# FX1 register map
Vendor: FTEL; File version: VP_FX1_V3.0_ISP_1.07
Registers are 32-bit, read-write, reset 0x0 unless marked. A register's access mark holds for its fields unless they carry their own. Offsets are from the block's base; [hi:lo] are bit positions; lines under a group give offsets from that group; {n}, {i} and the like mark numbered series.

## ISP (part 1 of 4) — ISP FX1 CSR v1.07 + VP extension 0x20261109 (ISP-UPD-001/002/007); FX1 header is authoritative.
Base 0x11000000
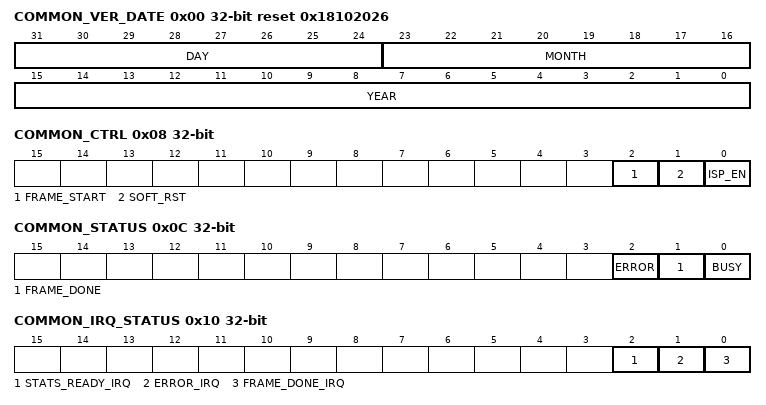
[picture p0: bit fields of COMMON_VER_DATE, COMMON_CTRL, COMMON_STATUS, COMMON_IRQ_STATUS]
0x00 COMMON_VER_DATE ro reset 0x18102026 — Fixed register-map revision date, BCD; not a build timestamp. [access=ro]
  [31:24] DAY — Version Date - Day Day of month, BCD. [access=ro]
  [23:16] MONTH — Version Date - Month Month, BCD. [access=ro]
  [15:0] YEAR — Version Date - Year Year, BCD. Reads 0x2026 for the current map. [access=ro]
0x04 COMMON_VER_ID ro reset 0x10007 — Pipeline programming ABI revision 1.07. Bayer RAW12 statistics, preset-only scaling, channel crop and wide CSC range arithmetic. [access=ro]
  [31:0] VERSION — Pipeline ABI 0x00010007; no per-block revision registers. [access=ro]
0x08 COMMON_CTRL — COMMON: global pipeline control. ISP_EN enables pipeline operation; supported optional blocks also use their own enable controls. [access=mixed]
  [2] FRAME_START write-1-sets — Software Frame Trigger (compatibility) Retained for register compatibility only. A write of 1 is accepted, self-clears and has no effect on the input DMA, admission or any other state. The input DMA starts a frame whenever its head buffer is valid; mark exactly one input buffer valid for single-shot operation. [access=w1s]
  [1] SOFT_RST write-1-sets — Request group recovery: stop admission, drain bus/internal work, then 15-clock reset pulse. Poll COMMON_RECOVERY_STATUS.BUSY/DONE for completion; copy abort records before restart. Busy requests rejected with TUNE_ERROR.PENDING. [access=w1sc]
  [0] ISP_EN — ISP Pipeline Enable 1 enables pipeline operation. Configure geometry and tuning first, then enable the pipeline before arming/enabling DMA so derived output geometry is valid. [access=rw]
0x0C COMMON_STATUS ro — COMMON: global pipeline status, read-only. [access=ro]
  [2] ERROR — Error Present Live OR of DMA_ERR ALIGN/AXI_RD/AXI_WR, LSC_ERROR, EE_STATUS.ERROR and TUNE_ERROR; flow-control and statistics-drop conditions are excluded. See those registers for the cause. [access=ro]
  [1] FRAME_DONE — Frame Complete 1 = the most recently admitted frame has retired on every enabled output, successfully or by recovery. Clears at the next accepted ingress SOF and on reset. [access=ro]
  [0] BUSY — Pipeline Busy 1 = a frame is in flight somewhere in the pipeline. [access=ro]
0x10 COMMON_IRQ_STATUS write-1-clears — COMMON: interrupt status. Sticky; write 1 to clear a bit. A bit sets regardless of the corresponding COMMON_IRQ_EN mask -- the mask gates the interrupt output, not the status. [access=w1c]
  [2] STATS_READY_IRQ write-1-clears — Statistics-Ready Interrupt Status Set when a statistics block publishes a completed frame. Write 1 to clear. [access=w1c]
  [1] ERROR_IRQ write-1-clears — Error Interrupt Status Set when DMA_ERR ALIGN, AXI_RD or AXI_WR, any LSC_ERROR bit, EE_STATUS.ERROR or any TUNE_ERROR bit changes from 0 to 1, and on every accepted recovery of any cause. IDMA_UNDERRUN, ODMA_OVERFLOW and statistics drops do not set it. Write 1 to clear. [access=w1c]
  [0] FRAME_DONE_IRQ write-1-clears — Frame-Done Interrupt Status Set when COMMON_STATUS.FRAME_DONE rises. Write 1 to clear. [access=w1c]
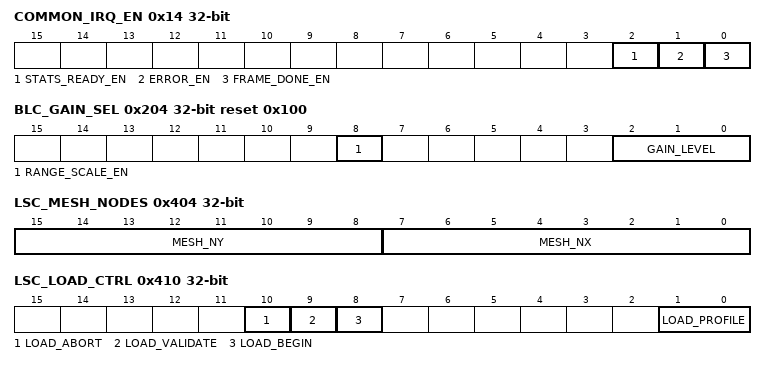
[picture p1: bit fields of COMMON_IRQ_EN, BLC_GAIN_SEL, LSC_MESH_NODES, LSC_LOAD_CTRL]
0x14 COMMON_IRQ_EN — COMMON: interrupt enable mask. Each bit gates whether the matching COMMON_IRQ_STATUS bit drives the interrupt output; the status bit sets either way. [access=rw]
  [2] STATS_READY_EN — Statistics-Ready Interrupt Enable 1 = statistics-ready contributes to the interrupt output. [access=rw]
  [1] ERROR_EN — Error Interrupt Enable 1 = error contributes to the interrupt output. [access=rw]
  [0] FRAME_DONE_EN — Frame-Done Interrupt Enable 1 = frame-done contributes to the interrupt output. [access=rw]
0x18 COMMON_FRAME_WIDTH reset 0x780 — COMMON: input frame width before Bayer phase alignment. The Input Formatter may discard one leading column, then rounds the remaining width down to even. Program legal DMA geometry. Input-domain changes require stopped/drained legacy mode; reject in profile mode with MODE, preserve state. Accepted changes invalidate dependent LSC/EE residents and output geometry. [access=rw]
  [15:0] H_ACTIVE — External Samples Per Line Even external input width before Bayer phase trim, 32..3842. Active W=(Win-SH)&~1 must be 32..3840. IDMA reads the external width; downstream coordinates use the derived active width. [access=rw]
0x1C COMMON_FRAME_HEIGHT reset 0x438 — COMMON: input frame height before Bayer phase alignment. The Input Formatter may discard one leading row, then rounds the remaining height down to even. Input DMA requires an even input height. Input-domain changes require stopped/drained legacy mode; reject in profile mode with MODE, preserve state. Accepted changes invalidate dependent LSC/EE residents and output geometry. [access=rw]
  [15:0] V_ACTIVE — External Lines Per Frame Even external input height before Bayer phase trim, 32..2162. Active H=(Hin-SV)&~1 must be 32..2160. IDMA reads the external height; downstream coordinates use the derived active height. [access=rw]
0x20 COMMON_BAYER — COMMON: Bayer phase of the incoming raw image. The Input Formatter aligns to RGGB by optional leading-column/row removal, then rounds each remaining dimension down to even. Input-domain changes require stopped/drained legacy mode; reject in profile mode with MODE, preserve state. Accepted changes invalidate dependent LSC/EE residents and output geometry. [access=rw]
  [1:0] PATTERN — Bayer Colour-Filter Pattern Bits [1:0] = [vertical shift, horizontal shift]. 0x0 = RGGB 0x1 = GRBG 0x2 = GBRG 0x3 = BGGR [access=rw]
0x28 COMMON_SCRATCH — COMMON: scratch register, no hardware effect. A plain 32-bit RW location, useful for proving the register bus is alive before trusting anything else read from it. [access=rw]
  [31:0] SCRATCH — Scratch Value Reads back whatever was written. [access=rw]
0x200 BLC_CTRL — BLC: black level correction control. Subtracts the sensor's dark pedestal, then optionally rescales the remaining range so that full scale is restored. [access=rw]
  [0] EN — Black Level Correction Enable 1 = subtract the pedestal, 0 = pass through unchanged. [access=rw]
0x204 BLC_GAIN_SEL reset 0x100 — Select BLC profile G0..G7 (ISP-UPD-002). Apply per-channel scale of selected BLC profile; 0 selects unity. [access=rw]
  [8] RANGE_SCALE_EN — Apply per-channel scale of selected BLC profile; 0 selects unity. [access=rw]
  [2:0] GAIN_LEVEL — Select BLC profile G0..G7 (ISP-UPD-002). [access=rw]
{0x208+0x14*i} BLC_OFS_G{i}_DFT reset 0xC8 (i=0..3) — BLC: profile G{i} shared pedestal. Subtracted from every channel; the per-channel registers add a trim on top. [access=rw]
  [11:0] OFS_G{i}_DFT — Profile G{i} Shared Black Level Unsigned 12-bit Bayer code, 0..4095. The shared pedestal and selected channel trim are added exactly in 13 bits before subtraction, without wrap or saturation; the residual clamps at zero. Reset 200. [access=rw]
{0x20C+0x14*i} BLC_OFS_G{i}_R (i=0..3) — BLC: profile G{i} red trim. [access=rw]
  [11:0] OFS_G{i}_R — Profile G{i} Red Black Level Trim Unsigned 12-bit Bayer code, 0..4095. The shared pedestal and selected channel trim are added exactly in 13 bits before subtraction, without wrap or saturation; the residual clamps at zero. Reset 0. [access=rw]
{0x210+0x14*i} BLC_OFS_G{i}_GR (i=0..3) — BLC: profile G{i} green-on-red-row trim. [access=rw]
  [11:0] OFS_G{i}_GR — Profile G{i} Green-Red Black Level Trim Unsigned 12-bit Bayer code, 0..4095. The shared pedestal and selected channel trim are added exactly in 13 bits before subtraction, without wrap or saturation; the residual clamps at zero. Reset 0. [access=rw]
{0x214+0x14*i} BLC_OFS_G{i}_GB (i=0..3) — BLC: profile G{i} green-on-blue-row trim. [access=rw]
  [11:0] OFS_G{i}_GB — Profile G{i} Green-Blue Black Level Trim Unsigned 12-bit Bayer code, 0..4095. The shared pedestal and selected channel trim are added exactly in 13 bits before subtraction, without wrap or saturation; the residual clamps at zero. Reset 0. [access=rw]
{0x218+0x14*i} BLC_OFS_G{i}_B (i=0..3) — BLC: profile G{i} blue trim. [access=rw]
  [11:0] OFS_G{i}_B — Profile G{i} Blue Black Level Trim Unsigned 12-bit Bayer code, 0..4095. The shared pedestal and selected channel trim are added exactly in 13 bits before subtraction, without wrap or saturation; the residual clamps at zero. Reset 0. [access=rw]
{0x218+0x14*i} BLC_OFS_G{i}_DFT reset 0xC8 (i=4..7) — BLC_OFS_G{i}_DFT; FX1 VP extension. [access=rw]
  [11:0] OFS_G{i}_DFT — OFS_G{i}_DFT [access=rw]
{0x21C+0x14*i} BLC_OFS_G{i}_R (i=4..7) — BLC_OFS_G{i}_R; FX1 VP extension. [access=rw]
  [11:0] OFS_G{i}_R — OFS_G{i}_R [access=rw]
{0x220+0x14*i} BLC_OFS_G{i}_GR (i=4..7) — BLC_OFS_G{i}_GR; FX1 VP extension. [access=rw]
  [11:0] OFS_G{i}_GR — OFS_G{i}_GR [access=rw]
{0x224+0x14*i} BLC_OFS_G{i}_GB (i=4..7) — BLC_OFS_G{i}_GB; FX1 VP extension. [access=rw]
  [11:0] OFS_G{i}_GB — OFS_G{i}_GB [access=rw]
{0x228+0x14*i} BLC_OFS_G{i}_B (i=4..7) — BLC_OFS_G{i}_B; FX1 VP extension. [access=rw]
  [11:0] OFS_G{i}_B — OFS_G{i}_B [access=rw]
{0x2B8+0x10*i} BLC_SCALE_G{i}_R reset 0x10000 (i=0..7) — BLC_SCALE_G{i}_R; FX1 VP extension. [access=rw]
  [17:0] SCALE_G{i}_R — SCALE_G{i}_R [access=rw]
{0x2BC+0x10*i} BLC_SCALE_G{i}_GR reset 0x10000 (i=0..7) — BLC_SCALE_G{i}_GR; FX1 VP extension. [access=rw]
  [17:0] SCALE_G{i}_GR — SCALE_G{i}_GR [access=rw]
{0x2C0+0x10*i} BLC_SCALE_G{i}_GB reset 0x10000 (i=0..7) — BLC_SCALE_G{i}_GB; FX1 VP extension. [access=rw]
  [17:0] SCALE_G{i}_GB — SCALE_G{i}_GB [access=rw]
{0x2C4+0x10*i} BLC_SCALE_G{i}_B reset 0x10000 (i=0..7) — BLC_SCALE_G{i}_B; FX1 VP extension. [access=rw]
  [17:0] SCALE_G{i}_B — SCALE_G{i}_B [access=rw]
0x400 LSC_CTRL — LSC: lens shading correction control. Multiplies each Bayer sample by a gain interpolated from a mesh, correcting the lens's corner falloff. [access=rw]
  [0] EN — Lens Shading Correction Enable 1 = apply the mesh gains, 0 = pass through unchanged. Has no effect unless a profile has been loaded and validated -- see LSC_PROFILE_STATUS. [access=rw]
0x404 LSC_MESH_NODES — LSC: mesh geometry, shared by all profiles. The reset value of zero is deliberately invalid: a mesh must be described before it can be loaded, and zero nodes cannot be. Global mesh shape, outside TUNE_BANK. Change only after full drain, leaving profile mode and releasing all sealed resident pins; invalidates mesh confirmations. [access=rw]
  [15:8] MESH_NY — Mesh Vertical Node Count Legal range 2..32, not exceeding active image height. Cells partition height-1 across ny-1 intervals; integer spacing may differ by one line. [access=rw]
  [7:0] MESH_NX — Mesh Horizontal Node Count Legal range 2..32, not exceeding active image width. Cells partition width-1 across nx-1 intervals; integer spacing may differ by one sample. Geometry changes invalidate resident profiles. [access=rw]
0x408 LSC_STRENGTH — LSC: how much of the mesh correction to apply. Blends between no correction and the full mesh, so one calibration can be backed off without reloading it. [access=rw]
  [16:0] STRENGTH — Correction Strength UQ1.16. Legal range 0..0x10000: zero gives unity and 0x10000 applies the full mesh. Larger representable codes extrapolate correction; negative effective gain clamps the pixel to zero. [access=rw]
0x40C LSC_PROFILE_SEL — LSC: which resident profile the pipeline uses. Three profiles are held so a different illuminant can be selected without a reload. Legacy mode: selecting an unloaded profile is refused and sets LSC_ERROR.profile_sel_reject. Profile mode: a bank scalar stored without check; SEAL rejects code 3 (INVALID) or an enabled selection of an invalid resident (NOT_READY). [access=rw]
  [1:0] PROFILE_SEL — Active Profile Select 0..2. Code 3 is invalid: rejected at the write in legacy mode, rejected by SEAL in profile mode. [access=rw]
0x410 LSC_LOAD_CTRL — LSC: sequential mesh loading into an inactive profile. Issue LOAD_BEGIN, write exactly 4*nx*ny coefficients, then LOAD_VALIDATE. Command priority is ABORT, VALIDATE, BEGIN. Begin while busy or validate while idle sets LOAD_PROTOCOL. Profile mode additionally sets TUNE_ERROR.LOCKED for every rejected destination (sealed, pending or in-flight); an in-flight destination sets both LOCKED and ACTIVE_LOAD_REJECT. [access=mixed]
  [10] LOAD_ABORT write-1-sets — Abort Coefficient Load Write 1 to discard the partial load and return to idle; self-clearing. The destination remains invalid until reloaded and validated. The active profile is unchanged. [access=w1s]
  [9] LOAD_VALIDATE write-1-sets — Validate Coefficient Load Write 1 to finish a load; self-clearing. Checks the coefficient count and marks the profile valid only if it matches. [access=w1s]
  [8] LOAD_BEGIN write-1-sets — Begin Coefficient Load Write 1 to start a load; self-clearing. [access=w1s]
  [1:0] LOAD_PROFILE — Load Destination Profile Destination profile for the load, 0..2. Loading the active profile is refused with ACTIVE_LOAD_REJECT. Active means selected by an admitted, unretired frame with LSC enabled, or in legacy mode the LSC_PROFILE_SEL profile while LSC_CTRL.EN=1 and ACTIVE_VALID=1. After reset no profile is active. [access=rw]
0x414 LSC_COEF_DATA — Node gain UQ4.18 [21:0]; unity 0x40000, maximum 8x (0x200000), ISP-UPD-001. [access=rw]
  [21:0] COEF_DATA
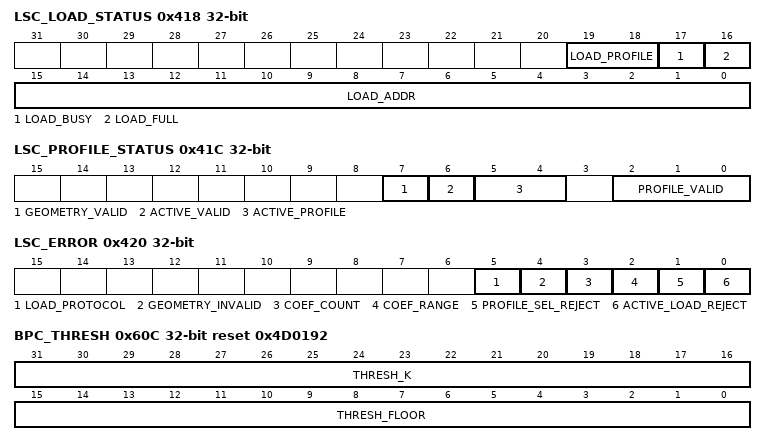
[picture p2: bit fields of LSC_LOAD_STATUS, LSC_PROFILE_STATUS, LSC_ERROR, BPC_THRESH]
0x418 LSC_LOAD_STATUS ro — LSC: progress of a load in flight, read-only. [access=ro]
  [19:18] LOAD_PROFILE — Profile Being Loaded Profile the load in progress is targeting. [access=ro]
  [17] LOAD_BUSY — Load In Progress 1 = a load is in progress. [access=ro]
  [16] LOAD_FULL — Load Complete 1 = the expected 4*nx*ny coefficients have been written. [access=ro]
  [15:0] LOAD_ADDR — Coefficients Accepted Number of coefficients accepted so far in this load. [access=ro]
0x41C LSC_PROFILE_STATUS ro — LSC: which profiles hold valid data, read-only. [access=ro]
  [7] GEOMETRY_VALID — Mesh Geometry Valid 1 = LSC_MESH_NODES describes a mesh the block can use. [access=ro]
  [6] ACTIVE_VALID — Active Profile Valid 1 = the active profile holds valid data. If this is 0 the correction is not applied however LSC_CTRL.en is set. [access=ro]
  [5:4] ACTIVE_PROFILE — Profile In Use Profile the pipeline is currently using. [access=ro]
  [2:0] PROFILE_VALID — Per-Profile Valid Flags One bit per resident profile; 1 = loaded and validated. bit 0 = PROFILE_0 bit 1 = PROFILE_1 bit 2 = PROFILE_2 [access=ro]
0x420 LSC_ERROR write-1-clears — LSC: sticky error flags. Write 1 to clear. Sticky because a load is a long sequence: an error part-way through must survive until software finishes and checks. [access=w1c]
  [5] LOAD_PROTOCOL write-1-clears — Load Protocol Violation The load sequence was violated -- data written with no load open or after LOAD_FULL, or validate without begin. [access=w1c]
  [4] GEOMETRY_INVALID write-1-clears — Invalid Mesh Geometry The mesh geometry is outside the supported node counts. [access=w1c]
  [3] COEF_COUNT write-1-clears — Coefficient Count Mismatch At validate, the number of coefficients written did not equal 4*nx*ny, or a write after LOAD_FULL was discarded. [access=w1c]
  [2] COEF_RANGE write-1-clears — Coefficient Out Of Range A written coefficient exceeded the legal gain range 0..4 inclusive in UQ3.18, or LOAD_VALIDATE found such a coefficient in the load. The load stays invalid until the next LOAD_BEGIN or LOAD_ABORT; clearing this bit does not make it valid. Sticky W1C; a simultaneous new error wins over clear. [access=w1c]
  [1] PROFILE_SEL_REJECT write-1-clears — Invalid Profile Selected LSC_PROFILE_SEL selected an invalid or unloaded profile. [access=w1c]
  [0] ACTIVE_LOAD_REJECT write-1-clears — Load Targeted Active Profile A load targeted the profile currently in use. [access=w1c]
0x424 LSC_STAT_OVF_CNT_R ro — LSC: red samples driven to saturation by the correction. Measured over the completed frame. A large count means the mesh gain is lifting highlights past full scale. [access=ro]
  [20:0] OVF_CNT_R — Red Saturated Sample Count Saturated red sample count for the last completed frame. [access=ro]
0x428 LSC_STAT_OVF_CNT_GR ro — LSC: green-on-red-row samples driven to saturation by the correction. Measured over the completed frame. A large count means the mesh gain is lifting highlights past full scale. [access=ro]
  [20:0] OVF_CNT_GR — Green-Red Saturated Sample Count Saturated green-on-red-row sample count for the last completed frame. [access=ro]
0x42C LSC_STAT_OVF_CNT_GB ro — LSC: green-on-blue-row samples driven to saturation by the correction. Measured over the completed frame. A large count means the mesh gain is lifting highlights past full scale. [access=ro]
  [20:0] OVF_CNT_GB — Green-Blue Saturated Sample Count Saturated green-on-blue-row sample count for the last completed frame. [access=ro]
0x430 LSC_STAT_OVF_CNT_B ro — LSC: blue samples driven to saturation by the correction. Measured over the completed frame. A large count means the mesh gain is lifting highlights past full scale. [access=ro]
  [20:0] OVF_CNT_B — Blue Saturated Sample Count Saturated blue sample count for the last completed frame. [access=ro]
0x600 BPC_CTRL — BPC: bad pixel correction control. Replaces pixels that disagree with their same-colour neighbours. [access=rw]
  [0] EN — Bad Pixel Correction Enable 1 = detect and correct, 0 = pass through unchanged. [access=rw]
0x604 BPC_MODE reset 0x1 — BPC_MODE: reserved compatibility control. The MAS specifies spatial BPC with immediate correction and no cross-frame defect history. Writes retain the field value but do not enable temporal detection. [access=rw]
  [0] DYNAMIC_DET_EN — Dynamic Detection Enable (reserved) No effect on the spatial BPC behavior specified by this MAS. [access=rw]
0x608 BPC_TEMPORAL_VAR reset 0x100 — BPC_TEMPORAL_VAR: reserved compatibility control. The MAS specifies spatial BPC with immediate correction and no cross-frame defect history. Writes retain the field value but do not enable temporal detection. [access=rw]
  [15:0] TEMPORAL_VAR — Inter-Frame Value Tolerance (reserved) No effect on the spatial BPC behavior specified by this MAS. [access=rw]
0x60C BPC_THRESH reset 0x4D0192 — BPC: detection threshold. A pixel is a candidate when it differs from its neighbourhood average by more than max(THRESH_FLOOR, THRESH_K * activity), where activity is the spread of the eight same-colour neighbours -- a relative term so textured areas are not over-corrected, and an absolute floor that always applies. [access=rw]
  [31:16] THRESH_K — Relative Detection Slope Relative slope, UQ8.8; 256 = 1.0. Reset 77 = 0.30. 0 disables the relative term and leaves the floor. [access=rw]
  [15:0] THRESH_FLOOR — Absolute Detection Floor Absolute threshold in pipeline (12-bit) code units, always applied. [access=rw]
0x610 BPC_PIXEL_AGE reset 0x4B0 — BPC_PIXEL_AGE: reserved compatibility control. The MAS specifies spatial BPC with immediate correction and no cross-frame defect history. Writes retain the field value but do not enable temporal detection. [access=rw]
  [15:0] PIXEL_AGE — Confirmation Frame Count (reserved) No effect on the spatial BPC behavior specified by this MAS. [access=rw]
0x614 BPC_NUM_CANDIDATES ro — BPC: per-frame spatial candidate count, read-only; saturates at 16383. [access=ro]
  [13:0] CANDIDATES — Spatial Candidate Count Candidate count of the most recently completed frame: pixels whose absolute difference from the truncated eight-neighbour average strictly exceeds the floor (THRESH_FLOOR, or the colour FLOOR when TUNE_BPC_CTRL.COLOR_THRESH_EN=1). Published at frame end and stable until the next frame completes; saturates at 16383. [access=ro]
0x618 BPC_NUM_DEFECTIVE ro — BPC: per-frame corrected-pixel count, read-only; saturates at 16383. [access=ro]
  [13:0] DEFECTIVE — Corrected Pixel Count Corrected-pixel count of the most recently completed frame, including factory-listed sites. Published at frame end with BPC_NUM_CANDIDATES and stable until the next frame completes; saturates at 16383. [access=ro]
0x61C BPC_STATUS write-1-clears — BPC: sticky status. Write 1 to clear. [access=w1c]
  [0] CAND_REJECT_OVF write-1-clears — Candidate Table Overflow (reserved for temporal tracking) Not asserted by the spatial BPC contract, which carries no defect table between frames. Spatial candidate and corrected-pixel counters saturate silently at 16383; saturation does not set this bit. [access=w1c]
0x800 WB_CTRL — WB: white balance control. Scales each Bayer channel so a neutral subject reads equal in R, G and B. [access=rw]
  [0] EN — White Balance Enable 1 = apply the channel gains, 0 = pass through unchanged. [access=rw]
0x804 WB_GAIN_R reset 0x100 — WB: red channel gain. [access=rw]
  [11:0] GAIN_R — Red Channel Gain UQ4.8 for R only; 0x100 = 1.0. Legacy mode uses WB_GAIN_G for both greens; profile mode uses WB_GAIN_G for Gr and TUNE_WB_GB for Gb. [access=rw]
0x808 WB_GAIN_G reset 0x100 — WB: green gain; both greens in legacy mode, Gr in profile mode. [access=rw]
  [11:0] GAIN_G — Green Channel Gain UQ4.8, 0x100 = 1.0. Legacy mode applies this gain to Gr and Gb. Profile mode applies it to Gr; TUNE_WB_GB independently controls Gb. [access=rw]
0x80C WB_GAIN_B reset 0x100 — WB: blue channel gain. [access=rw]
  [11:0] GAIN_B — Blue Channel Gain UQ4.8 for B only; 0x100 = 1.0. Legacy mode uses WB_GAIN_G for both greens; profile mode uses WB_GAIN_G for Gr and TUNE_WB_GB for Gb. [access=rw]
0xA00 DG_CTRL — DG: digital gain control. A single multiplier on every channel, applied after white balance. Unlike sensor analogue gain this cannot improve signal-to-noise -- it amplifies the noise with the signal -- so prefer raising the sensor's gain first. [access=rw]
  [0] EN — Digital Gain Enable 1 = apply the gain, 0 = pass through unchanged. [access=rw]
0xA04 DG_GAIN reset 0x100 — DG: global digital gain. [access=rw]
  [11:0] GAIN — Global Digital Gain UQ4.8; 0x100 = 1.0. Maximum 0xFFF is just under 16x. [access=rw]
0xC00 D_WDR_CTRL — D_WDR: reserved for a future function. Register storage is present; writes have no effect on image processing in this MAS. [access=rw]
  [0] EN — Digital WDR Enable (not implemented) Reserved; no processing effect in this MAS. [access=rw]
0xC04 D_WDR_STRENGTH — D_WDR: tone compression strength. NOT IMPLEMENTED -- see D_WDR_CTRL. [access=rw]
  [7:0] STRENGTH — Tone Compression Strength (not implemented) Reserved; no processing effect in this MAS. [access=rw]
0xE00 DEMOSAIC_STATUS ro — DEMOSAIC: block status. [access=ro]
  [0] BUSY — The Demosaic Block Busy 1 while the block holds in-flight pixels. Follow the block-specific configuration and LUT loading sequence; busy alone does not grant permission to rewrite live tables. [access=ro]
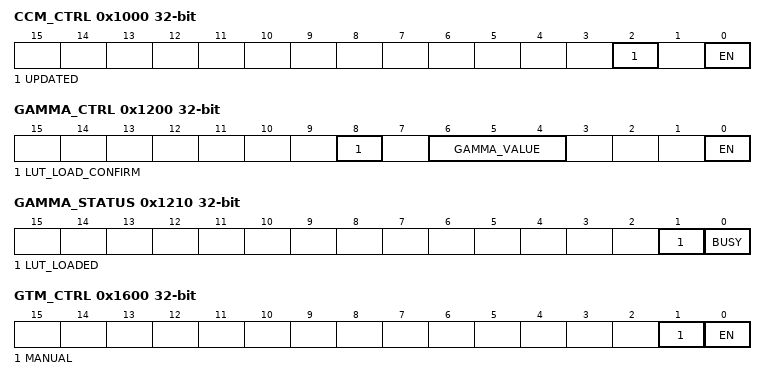
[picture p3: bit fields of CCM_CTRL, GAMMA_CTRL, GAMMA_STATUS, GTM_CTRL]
0x1000 CCM_CTRL — CCM: colour correction matrix control. Converts the sensor's native colour response to the working colour space by a 3x3 matrix plus per-channel offset. The matrix is not optional in the datapath -- clearing the enable applies the identity, it does not remove the block's latency. [access=rw]
  [2] UPDATED — Reserved Update Control Readable/writable compatibility field. Configuration is captured at accepted SOF; no explicit update command is required. [access=rw]
  [0] EN — Colour Matrix Enable 1 = apply the matrix, 0 = pass through unchanged. [access=rw]
0x1004 CCM_CRR reset 0x200 — CCM: matrix coefficient (0,0), red from red. [access=rw]
  [11:0] COEFRR — Matrix Coefficient Red-from-Red Signed two's-complement Q3.9, 12 bits. Unity is 0x200; range -4.0 through 4.0-1/512. Offsets use the same fractional scale as the accumulator and are added before the final shift. [access=rw]
0x1008 CCM_CRG — CCM: matrix coefficient (0,1), red from green. [access=rw]
  [11:0] COEFRG — Matrix Coefficient Red-from-Green Signed two's-complement Q3.9, 12 bits. Unity is 0x200; range -4.0 through 4.0-1/512. Offsets use the same fractional scale as the accumulator and are added before the final shift. [access=rw]
0x100C CCM_CRB — CCM: matrix coefficient (0,2), red from blue. [access=rw]
  [11:0] COEFRB — Matrix Coefficient Red-from-Blue Signed two's-complement Q3.9, 12 bits. Unity is 0x200; range -4.0 through 4.0-1/512. Offsets use the same fractional scale as the accumulator and are added before the final shift. [access=rw]
0x1010 CCM_CGR — CCM: matrix coefficient (1,0), green from red. [access=rw]
  [11:0] COEFGR — Matrix Coefficient Green-from-Red Signed two's-complement Q3.9, 12 bits. Unity is 0x200; range -4.0 through 4.0-1/512. Offsets use the same fractional scale as the accumulator and are added before the final shift. [access=rw]
0x1014 CCM_CGG reset 0x200 — CCM: matrix coefficient (1,1), green from green. [access=rw]
  [11:0] COEFGG — Matrix Coefficient Green-from-Green Signed two's-complement Q3.9, 12 bits. Unity is 0x200; range -4.0 through 4.0-1/512. Offsets use the same fractional scale as the accumulator and are added before the final shift. [access=rw]
0x1018 CCM_CGB — CCM: matrix coefficient (1,2), green from blue. [access=rw]
  [11:0] COEFGB — Matrix Coefficient Green-from-Blue Signed two's-complement Q3.9, 12 bits. Unity is 0x200; range -4.0 through 4.0-1/512. Offsets use the same fractional scale as the accumulator and are added before the final shift. [access=rw]
0x101C CCM_CBR — CCM: matrix coefficient (2,0), blue from red. [access=rw]
  [11:0] COEFBR — Matrix Coefficient Blue-from-Red Signed two's-complement Q3.9, 12 bits. Unity is 0x200; range -4.0 through 4.0-1/512. Offsets use the same fractional scale as the accumulator and are added before the final shift. [access=rw]
0x1020 CCM_CBG — CCM: matrix coefficient (2,1), blue from green. [access=rw]
  [11:0] COEFBG — Matrix Coefficient Blue-from-Green Signed two's-complement Q3.9, 12 bits. Unity is 0x200; range -4.0 through 4.0-1/512. Offsets use the same fractional scale as the accumulator and are added before the final shift. [access=rw]
0x1024 CCM_CBB reset 0x200 — CCM: matrix coefficient (2,2), blue from blue. [access=rw]
  [11:0] COEFBB — Matrix Coefficient Blue-from-Blue Signed two's-complement Q3.9, 12 bits. Unity is 0x200; range -4.0 through 4.0-1/512. Offsets use the same fractional scale as the accumulator and are added before the final shift. [access=rw]
0x1028 CCM_OFS_R — Signed 12-bit offset in output pixel levels; code 1 adds one level (ISP-UPD-007). [access=rw]
  [11:0] OFFSET_R
0x102C CCM_OFS_G — Signed 12-bit offset in output pixel levels; code 1 adds one level (ISP-UPD-007). [access=rw]
  [11:0] OFFSET_G
0x1030 CCM_OFS_B — Signed 12-bit offset in output pixel levels; code 1 adds one level (ISP-UPD-007). [access=rw]
  [11:0] OFFSET_B
0x1034 CCM_STATUS ro — CCM: block status, read-only. [access=ro]
  [0] BUSY — Colour Matrix Busy 1 while the block holds in-flight pixels. Follow the block-specific configuration and LUT loading sequence; busy alone does not grant permission to rewrite live tables. [access=ro]
0x1200 GAMMA_CTRL — GAMMA: enable and explicit SRAM load confirmation. Hard reset and common soft reset in profile mode clear validity; legacy common soft reset preserves it. Writes invalidate the destination. Load and verify the complete curve before confirmation, following the selected control-mode ownership rules. [access=mixed]
  [8] LUT_LOAD_CONFIRM wo write-1-sets — Confirm all 256 entries written and verified while Gamma is disabled and idle. Reads zero. Any LUT write invalidates the table and dominates a coincident confirmation. [access=w1p]
  [6:4] GAMMA_VALUE — Curve Preset Select (reserved) Readable/writable compatibility field with no processing effect. Software constructs the curve and loads it through the LUT port. [access=rw]
  [0] EN — Gamma enable: apply the frame-selected curve only after LUT_LOADED is set; otherwise pass through unchanged. [access=rw]
0x1204 GAMMA_LUT_ADDR — GAMMA: LUT index. Auto-increments on every write to GAMMA_LUT_DATA, so a full curve is loaded by writing the address once and then 256 data values. [access=rw]
  [7:0] ADDR — Gamma LUT Index Entry index 0..255. Entry i is the output for input i/255 of full scale; the 8 index bits are the top 8 of each 12-bit component. [access=rw]
0x1208 GAMMA_LUT_DATA — GAMMA: LUT write port. The same value is written to all three channel tables -- the hardware has no per-channel curve. [access=rw]
  [11:0] DATA — Gamma LUT Write Data 12-bit output level, 0..4095. Reading this register returns the last value written, not the memory contents; use GAMMA_LUT_RDATA to read the curve back. [access=rw]
0x120C GAMMA_LUT_RDATA ro — GAMMA: table contents at GAMMA_LUT_ADDR, read-only. Address reads do not increment the index. [access=ro]
  [11:0] RDATA — Gamma LUT Read Data 12-bit contents of the selected entry. Memory contents are undefined before initialization; the reset-value column does not initialize RAM. [access=ro]
0x1210 GAMMA_STATUS ro — Gamma status. LUT_LOADED reports confirmed validity of curve bank 0 in both modes; bank-0 writes, INIT of bank 0, leaving profile mode, hard reset and profile-mode common soft reset clear it. An unloaded table bypasses correction. [access=ro]
  [1] LUT_LOADED — Software-confirmed validity of curve bank 0 in both modes; legacy confirmation and profile-mode GAMMA_CONFIRM of bank 0 set it. INIT of bank 0 and leaving profile mode also clear it. Hard reset and profile-mode common soft reset clear it; legacy common soft reset preserves it. Verify the complete curve before confirmation. An unloaded table bypasses Gamma. [access=ro]
  [0] BUSY — The Gamma Block Busy 1 while the block holds in-flight pixels. Follow the block-specific configuration and LUT loading sequence; busy alone does not grant permission to rewrite live tables. [access=ro]
0x1400 CSC_CTRL — CSC: RGB to YCbCr conversion, no bypass. STD selects BT.601 or BT.709; TUNE_CSC_CTRL.FULL_RANGE selects range independently, default full range. Optional look controls and wide intermediate arithmetic follow the frame profile. [access=rw]
  [0] STD — Colour Standard Select 0 BT.601 (reset), 1 BT.709. Held for the frame. Range is independently selected by TUNE_CSC_CTRL.FULL_RANGE, default full range. No bypass. CH2 inverse CSC uses matching frame-held standard and range. [access=rw]
0x1600 GTM_CTRL — GTM: automatic tone adaptation from a completed prior frame or a protected manual curve. Automatic updates are at least one frame delayed and may wait for curve completion and ownership; manual mode holds the software-selected curve. [access=rw]
  [1] MANUAL — Manual Curve Hold 1 holds automatic curve construction. Load the software curve with EN=0 and MANUAL=1, verify it, then enable. MANUAL does not permit memory writes while EN=1. Legacy mode applies manual bank 0 only when all 65 points are complete; otherwise samples pass through. [access=rw]
  [0] EN — Tone Mapping Enable 1 = apply the tone curve, 0 = pass through unchanged. [access=rw]
0x1604 GTM_LUT_ADDR — GTM: ratio LUT index. Auto-increments on every write to GTM_LUT_DATA. [access=rw]
  [6:0] ADDR — Tone Curve Index Control point 0..64. The table is 65 entries, not 64: sixty-four interpolation intervals plus the endpoint, which is why the field is 7 bits. Point i covers luma 4*i. Data writes at 65..127 are discarded and read back zero. [access=rw]
0x1608 GTM_LUT_DATA — GTM: ratio LUT write port. Memory updates only while GTM_CTRL.EN=0; enabled writes do not update the table. MANUAL=1 holds automatic construction during loading and use. [access=rw]
  [15:0] DATA — Tone Curve Write Data UQ8.8 ratio applied to that luma level; 256 = unity, below darkens, above brightens. Reading returns the shadow, not the table -- use GTM_LUT_RDATA. [access=rw]
0x160C GTM_KEY reset 0x2E — GTM: photographic key scales scene-referred luminance for automatic tone-curve construction; it does not guarantee the output arithmetic mean. [access=rw]
  [7:0] KEY — Photographic Key UQ0.8 photographic key. Reset 0x2E = 46/256 = 0.1796875, approximately 0.18. This is the automatic curve exposure parameter, not a guaranteed output mean. [access=rw]
0x1610 GTM_LWHITE reset 0x400 — GTM: the luminance that maps to white. Everything above this is compressed to full scale. The hardware forms the reciprocal itself. [access=rw]
  [15:0] LWHITE — White Point Luminance UQ8.8 relative to the scene average; reset 0x0400 = 4.0. [access=rw]
0x1614 GTM_ROI_LOG2 reset 0xB — GTM: centered metering window with nominal edge 2^n. Each axis independently clamps its exponent to floor(log2(active extent)), so the effective window may be rectangular. Power-of-two area permits shift normalization. [access=rw]
  [4:0] ROI_LOG2 — Metering Window Size (log2) Nominal edge 2^n, independently clamped to powers of two fitting the input width and height. Reset 11. Statistics are measured on input luma and the resulting automatic curve is used on a later frame. [access=rw]
0x1618 GTM_LUT_RDATA ro — GTM: ratio LUT read-back at GTM_LUT_ADDR, read-only. [access=ro]
  [15:0] RDATA — Tone Curve Read Data Profile mode: the TUNE_BANK-selected bank manual curve at GTM_LUT_ADDR; entries without both byte lanes written read zero; automatic curves are not readable. Legacy mode: manual bank 0 when MANUAL=1 (incomplete entries read zero), the most recently published automatic curve when MANUAL=0. [access=ro]
0x161C GTM_STATUS ro — GTM: block status. [access=ro]
  [0] BUSY — The Tone-Mapping Block Busy 1 while the block holds in-flight pixels. Follow the block-specific configuration and LUT loading sequence; busy alone does not grant permission to rewrite live tables. [access=ro]
0x1800 NR_2D_CTRL — NR_2D: spatial noise reduction control. A Haar-wavelet denoise whose strength follows a noise variance measured on the previous frame. [access=rw]
  [0] EN — 2D Noise Reduction Enable 1 = filter, 0 = pass through unchanged. This block routes the stream around the engine when disabled, so the change is held until the engine has drained rather than applied mid-frame. [access=rw]
